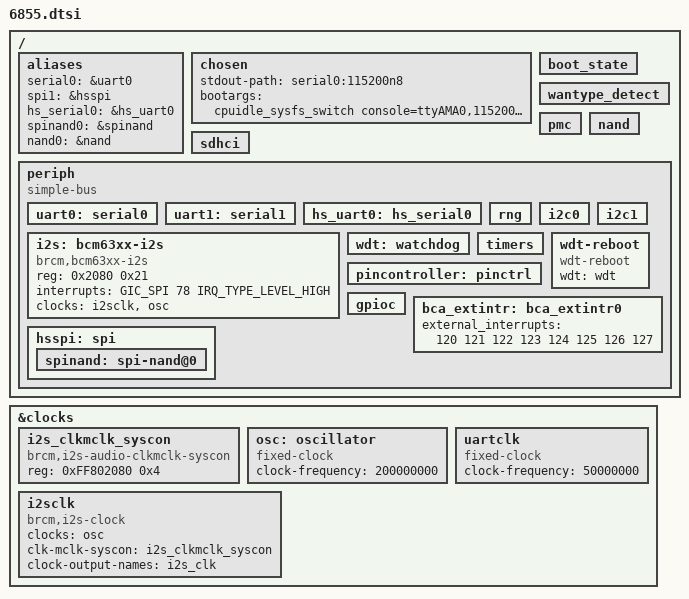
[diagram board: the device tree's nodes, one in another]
/dts-v1/;

#include "linux_autoconf.h"

#include <dt-bindings/interrupt-controller/arm-gic.h>
#include <dt-bindings/interrupt-controller/irq.h>

#include "../../boot_rsvdmem.dtsi"

	#define MODEL "Broadcom BCM96855"
	#define COMPATIBLE "brcm,bcm96855"

/ {
	aliases {
		serial0		= &uart0;
		spi1		= &hsspi; /* 0 = legacy, 1 = high speed */
		hs_serial0	= &hs_uart0;
		spinand0	= &spinand;
		nand0		= &nand;
	};

	chosen {
		stdout-path = "serial0:115200n8";
		bootargs = "cpuidle_sysfs_switch console=ttyAMA0,115200 earlycon rootwait";
	};

	/* memc */
	#include "../../ip/memc.dtsi"

	/* boot state */
	boot_state: boot_state {
		#define RESET_REASON_OFFSET		0xff802628
		#define RESET_REASON_SIZE		0x4
		#define RESET_STATUS_OFFSET		0xff85a018
		#define RESET_STATUS_SIZE		0x4
		#include "../../ip/bcm_boot_state_v2.dtsi"
	};

	/* wan type auto detect */
	wantype_detect {
		#define GPON_GENERAL_CONFIG_ADDR	0x828B9000
		#define GPON_GENERAL_CONFIG_SIZE	0x10
		#define EPON_TOP_ADDR			0x828B4000
		#define EPON_TOP_SIZE			0x1C
		#define EPON_LIF_ADDR			0x828B5800
		#define EPON_LIF_SIZE			0x110
		#define EPON_XPCSR_ADDR			0x828B7000
		#define EPON_XPCSR_SIZE			0x124
		#define NGPON_RXGEN_ADDR		0x828BC000
		#define NGPON_RXGEN_SIZE		0x80
		#include "../../ip/bcm_wantype_detect.dtsi"
	};

	/* PMC */
	pmc: pmc {
		#define PMC_REG_OFFSET              0xffb20060 
		#define PMC_REG_SIZE                0x1e0
		#include "../../ip/bcm_pmc_lite.dtsi"
	};

	/* NAND controller. Although it is on PERIPH bus, but to facilitate single
		device tree for linux/uboot and because uboot cannot interpret composite
		addresses has no scope */
	nand: nand {
		#define NAND_CTRL_OFFSET		0xff801800
		#define NAND_CTRL_SIZE			0x400
		#define NAND_INTR_OFFSET		0xff802000
		#define NAND_INTR_SIZE			0x10
		#define NAND_CACHE_OFFSET		0xff801C00
		#define NAND_CACHE_SIZE			0x200
		#include "../../ip/bcm_nand7_1.dtsi"
	};

	/* EMMC */
	sdhci: sdhci {
		#define SDHCI_OFFSET			0xff810000
		#define SDHCI_SIZE			0x100
		#define SDHCI_TOPCFG_OFFSET		0xff810100
		#define SDHCI_TOPCFG_SIZE		0x100
		#define SDHCI_BOOT_OFFSET		0xff810200
		#define SDHCI_BOOT_SIZE			0x40
		#define SDHCI_AHBSS_CTRL_OFFSET		0xff810300
		#define SDHCI_AHBSS_CTRL_SIZE		0x100
		#define SDIO_EMMC_SPI			86
		#include "../../ip/bcm_sdhci.dtsi"
	};

	/* clocks */
	#define PERIPH_CLK			200000000
	#define HS_SPI_PLL_CLK		200000000
	#include "../../ip/bcm_clocks.dtsi"

	periph {
		compatible = "simple-bus";
		#address-cells = <1>;
		#size-cells = <1>;
		ranges = <0x0 0xff800000 0x100000>;

		/* UART */
		uart0: serial0 {
			#define UART_OFFSET			0x12000
			#define UART_SIZE			0x1000
			#define UART_SPI			32
			#define UART_CLK_LABEL		refclk50mhz
			#define UART_CLK			50000000
			#include "../../ip/bcm_arm_uart.dtsi"
		};

		uart1: serial1 {
			#define UART_OFFSET			0x13000
			#define UART_SIZE			0x1000
			#define UART_SPI			33
			#define UART_CLK_LABEL		refclk50mhz
			#define UART_CLK			50000000
			#include "../../ip/bcm_arm_uart.dtsi"
		};

		hs_uart0: hs_serial0 {
			#define UART_OFFSET			0xff810400
			#define UART_SIZE			0x1E0
			#define UART_SPI			34
			#include "../../ip/bcm_hs_uart.dtsi"
		};

		rng: rng {
			#define RNG200_OFFSET		0x00000b80
			#define RNG200_SIZE			0x30
			#include "../../ip/bcm_rng200.dtsi"
		};

		/* i2c */
		i2c0: i2c0 {
			#define I2C_OFFSET			0x2100
			#define I2C_SIZE			0x60
			#include "../../ip/bcm_i2c_bus.dtsi"
		};

		i2c1: i2c1 {
			#define I2C_OFFSET			0x5a800
			#define I2C_SIZE			0x60
			#include "../../ip/bcm_i2c_bus.dtsi"
		};

		i2s: bcm63xx-i2s {
			compatible		= "brcm,bcm63xx-i2s";
			reg				= <0x2080 0x21>;
			interrupts		= <GIC_SPI 78 IRQ_TYPE_LEVEL_HIGH>;
			clocks			= <&i2sclk>, <&osc>;
			clock-names		= "i2sclk","i2sosc";
		};

		/* watchdog */
		wdt: watchdog {
			#define WATCHDOG_OFFSET		0x480
			#define WATCHDOG_SIZE		0x14
			#define WATCHDOG_TIMEOUT	80
			#include "../../ip/bcm_wdt.dtsi"
		};

		/* periph timers */
		timers: timers {
			#define TIMERS_OFFSET		0x400
			#define TIMERS__SIZE		0x48
			#define TIMER0_SPI			11
			#define TIMER1_SPI			12
			#define TIMER2_SPI			13
			#define TIMER3_SPI			14
			#include "../../ip/bcm_timer.dtsi"
		};

		/* watchdog reboot */
		wdt-reboot {
			compatible	= "wdt-reboot";
			wdt			= <&wdt>;
		};

		pincontroller: pinctrl {
			#define PINCTRL_OFFSET		0x554
			#define PINCTRL_SIZE		0xc
			#define PINCTRL_NUM_PINS	105
			#define PINCTRL_NUM_FUNC	8
			#define PINCTRL_GPIO_FUNC	4
			#include "../../ip/bcm_bca_pinctrl.dtsi"
			#include "6855_pinctrl.dtsi"
		};

		/* gpio */
		gpioc: gpioc {
			#define GPIO_DIR_OFFSET		0x500
			#define GPIO_DIR_SIZE		0x20
			#define GPIO_DATA_OFFSET	0x520
			#define GPIO_DATA_SIZE		0x20
			#define NUM_OF_GPIOS		105
			#include "../../ip/bcm_bca_gpio.dtsi"
		};

		/* external interrups */
		bca_extintr: bca_extintr0 {
			#define EXTINTR_OFFSET		0x4
			#define EXTINTR_SIZE		0x48
			#define MAX_EXT_INTR		8
			#include "../../ip/bcm_bca_extintr.dtsi"
			external_interrupts = <120 121 122 123 124 125 126 127>;
		};

		/* HS SPI */
		hsspi: spi {
			#define HS_SPI_OFFSET		0x1000
			#define HS_SPI_SIZE			0x600
			#define HS_SPI_MAX_FREQ		100000000
			#include "../../ip/bcm_hsspi.dtsi"

			spinand: spi-nand@0 {
				#define SPINAND_MAX_FREQ	50000000
				#include "../../ip/bcm_spinand.dtsi"
			};
		};
	};
};

&clocks {
	#address-cells = <1>;
	#size-cells    = <1>;
	ranges;

	i2s_clkmclk_syscon: i2s_clkmclk_syscon{
		compatible			= "brcm,i2s-audio-clkmclk-syscon", "syscon";
		reg					= <0xFF802080 0x4>;
	};
	osc: oscillator {
		#clock-cells		= <0>;
		compatible			= "fixed-clock";
		clock-frequency		= <200000000>;
	};

	i2sclk: i2sclk {
		#clock-cells		= <0>;
		compatible			= "brcm,i2s-clock";
		clocks				= <&osc>;
		clk-mclk-syscon		= <&i2s_clkmclk_syscon>;
		clock-output-names	= "i2s_clk";
	};

	uartclk: uartclk {
		compatible			= "fixed-clock";
		#clock-cells		= <0>;
		clock-frequency		= <50000000>;
	};
};

